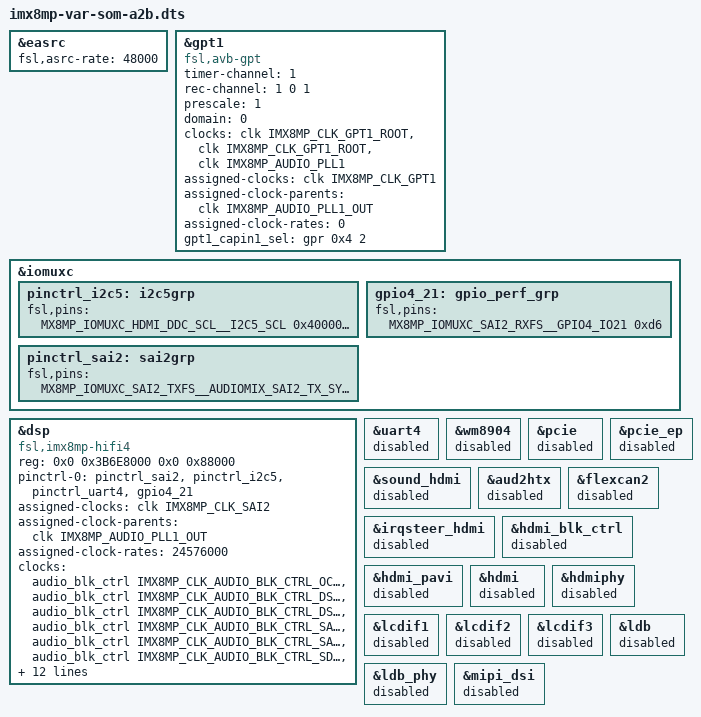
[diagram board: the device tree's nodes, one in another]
// Copyright AxisB Inc 2024

#include "imx8mp-var-som-symphony.dts"

/* Enable easrc */
&easrc {
	fsl,asrc-rate  = <48000>;
	status = "okay";
};

/* AVB HW timer */
&gpt1 {
	compatible = "fsl,avb-gpt";
	timer-channel = <1>; /* Use output compare channel 1*/
	rec-channel = <1 0 1>; // capture channel, eth port, ENET TC id
	prescale = <1>;
	domain = <0>;

	clocks = <&clk IMX8MP_CLK_GPT1_ROOT>,
		 <&clk IMX8MP_CLK_GPT1_ROOT>,
		 <&clk IMX8MP_AUDIO_PLL1>;
	clock-names = "ipg", "per", "audio_pll";

	/* Make the GPT clk root derive from the audio PLL*/
	assigned-clocks = <&clk IMX8MP_CLK_GPT1>;
	assigned-clock-parents = <&clk IMX8MP_AUDIO_PLL1_OUT>;
	assigned-clock-rates = <0>;

	gpt1_capin1_sel = <&gpr 0x4 2>;

	status = "okay";
};

&iomuxc {
	pinctrl_i2c5: i2c5grp {
		fsl,pins = <
			MX8MP_IOMUXC_HDMI_DDC_SCL__I2C5_SCL				0x400001c2
			MX8MP_IOMUXC_HDMI_DDC_SDA__I2C5_SDA				0x400001c2
		>;
	};

	pinctrl_sai2: sai2grp {
		fsl,pins = <
			MX8MP_IOMUXC_SAI2_TXFS__AUDIOMIX_SAI2_TX_SYNC			0xd6
			MX8MP_IOMUXC_SAI2_TXC__AUDIOMIX_SAI2_TX_BCLK			0xd6
			MX8MP_IOMUXC_SAI2_TXD0__AUDIOMIX_SAI2_TX_DATA00			0xd6
			MX8MP_IOMUXC_SAI2_RXD0__AUDIOMIX_SAI2_TX_DATA01			0xd6
			MX8MP_IOMUXC_SAI2_MCLK__AUDIOMIX_SAI2_MCLK			    0xd6
		>;
	};

    gpio4_21: gpio_perf_grp {
        fsl,pins = <
			MX8MP_IOMUXC_SAI2_RXFS__GPIO4_IO21			            0xd6
        >;
    };
};

&dsp {
	compatible = "fsl,imx8mp-hifi4";
	reg = <0x0 0x3B6E8000 0x0 0x88000>;
	pinctrl-names = "default";
	pinctrl-0 = <&pinctrl_sai2>, <&pinctrl_i2c5>, <&pinctrl_uart4>, <&gpio4_21>;
	assigned-clocks = <&clk IMX8MP_CLK_SAI2>;
	assigned-clock-parents = <&clk IMX8MP_AUDIO_PLL1_OUT>;
	assigned-clock-rates = <24576000>;
	clocks = <&audio_blk_ctrl IMX8MP_CLK_AUDIO_BLK_CTRL_OCRAMA_IPG>,
			 <&audio_blk_ctrl IMX8MP_CLK_AUDIO_BLK_CTRL_DSP_ROOT>,
			 <&audio_blk_ctrl IMX8MP_CLK_AUDIO_BLK_CTRL_DSPDBG_ROOT>,
			 <&audio_blk_ctrl IMX8MP_CLK_AUDIO_BLK_CTRL_SAI2_IPG>,
			 <&audio_blk_ctrl IMX8MP_CLK_AUDIO_BLK_CTRL_SAI2_MCLK1>,
			 <&audio_blk_ctrl IMX8MP_CLK_AUDIO_BLK_CTRL_SDMA3_ROOT>,
			 <&clk IMX8MP_CLK_I2C5_ROOT>,
			 <&audio_blk_ctrl IMX8MP_CLK_AUDIO_BLK_CTRL_ASRC_IPG>,
			 <&audio_blk_ctrl IMX8MP_CLK_AUDIO_BLK_CTRL_SAI2_MCLK1>,
			 <&clk IMX8MP_CLK_UART4_ROOT>;
	clock-names = "ocram", "core", "debug",
				  "per_clk1", "per_clk2", "per_clk3",
                  "per_clk4", "per_clk5", "per_clk6",
				  "per_clk7";
	firmware-name = "imx/dsp/hifi4.bin";
	power-domains = <&audiomix_pd>;
	mbox-names = "tx0", "rx0", "rxdb0";
	mboxes = <&mu2 0 0>,
			 <&mu2 1 0>,
			 <&mu2 3 0>;
	memory-region = <&dsp_vdev0buffer>, <&dsp_vdev0vring0>,
					<&dsp_vdev0vring1>, <&dsp_reserved>;
	syscon = <&audio_blk_ctrl>;
	status = "okay";
};

&uart4 {
	status = "disabled";
};

&wm8904 {
	status = "disabled";
};

&pcie {
    status = "disabled";
};

&pcie_ep {
    status = "disabled";
};

&sound_hdmi {
	status = "disabled";
};

&aud2htx {
	status = "disabled";
};

&flexcan2 {
	status = "disabled";
};

&irqsteer_hdmi {
	status = "disabled";
};

&hdmi_blk_ctrl {
	status = "disabled";
};

&hdmi_pavi {
	status = "disabled";
};

&hdmi {
	status = "disabled";
};

&hdmiphy {
	status = "disabled";
};

/* MIPI-DSI */
&lcdif1 {
	status = "disabled";
};

/* LVDS */
&lcdif2 {
	status = "disabled";
};

/* HDMI */
&lcdif3 {
	status = "disabled";
};

&ldb {
	status = "disabled";
};

&ldb_phy {
	status = "disabled";
};

&mipi_dsi {
	status = "disabled";
};
